# M4KN register map
File version: 0.1
Registers are 32-bit, read-write, reset 0x0 unless marked. A register's access mark holds for its fields unless they carry their own. Offsets are from the block's base; [hi:lo] are bit positions; {n}, {i} and the like mark numbered series.

## AMP — Gain Op-AMP (AMP)
Base 0x400BD000
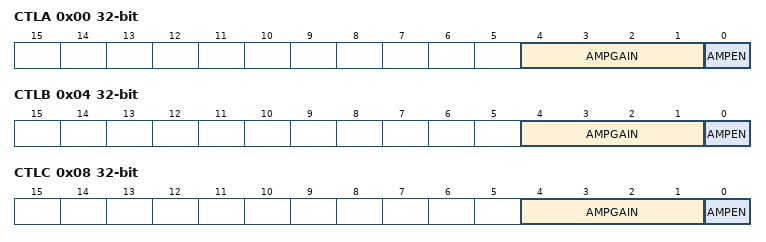
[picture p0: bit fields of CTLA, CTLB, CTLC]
0x00 CTLA — AMP control register A
  [4:1] AMPGAIN, [0] AMPEN
0x04 CTLB — AMP control register B
  [4:1] AMPGAIN, [0] AMPEN
0x08 CTLC — AMP control register C
  [4:1] AMPGAIN, [0] AMPEN

## T32A0 — 32-bit Timer Event Counter (T32A)
Base 0x400C1000
Same registers: T32A1 0x400C1400, T32A2 0x400C1800, T32A3 0x400C1C00, T32A4 0x400C2000, T32A5 0x400C2400
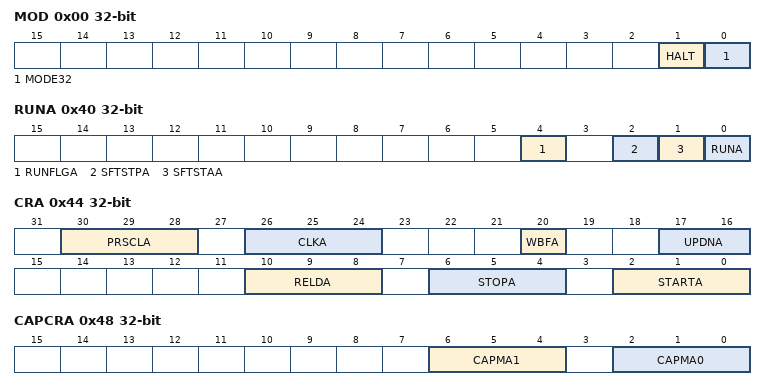
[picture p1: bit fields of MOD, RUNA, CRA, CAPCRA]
0x00 MOD — T32A Mode Register
  [1] HALT, [0] MODE32
0x40 RUNA — T32A Run Register A
  [4] RUNFLGA ro, [2] SFTSTPA wo, [1] SFTSTAA wo, [0] RUNA
0x44 CRA — T32A Control Register A
  [30:28] PRSCLA, [26:24] CLKA, [20] WBFA, [17:16] UPDNA, [10:8] RELDA, [6:4] STOPA, [2:0] STARTA
0x48 CAPCRA — T32A Capture Control Register A
  [6:4] CAPMA1, [2:0] CAPMA0
0x4C OUTCRA0 wo — T32A Output Control Register A0
  [1:0] OCRA
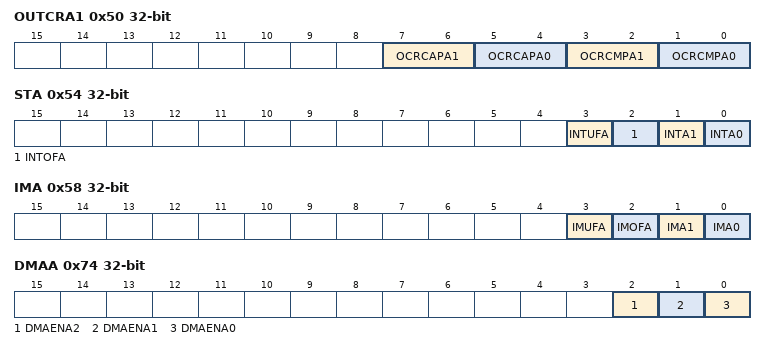
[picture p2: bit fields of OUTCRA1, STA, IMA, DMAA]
0x50 OUTCRA1 — T32A Output Control Register A1
  [7:6] OCRCAPA1, [5:4] OCRCAPA0, [3:2] OCRCMPA1, [1:0] OCRCMPA0
0x54 STA — T32A Status Register A
  [3] INTUFA, [2] INTOFA, [1] INTA1, [0] INTA0
0x58 IMA — T32A Interrupt Mask Register A
  [3] IMUFA, [2] IMOFA, [1] IMA1, [0] IMA0
0x5C TMRA ro — T32A Counter Capture Register A
  [15:0] TMRA
0x60 RELDA — T32A Reload Register A
  [15:0] RELDA
0x64 RGA0 — T32A Timer Register A0
  [15:0] RGA0
0x68 RGA1 — T32A Timer Register A1
  [15:0] RGA1
0x6C CAPA0 ro — T32A Capture Register A0
  [15:0] CAPA0
0x70 CAPA1 ro — T32A Capture Register A1
  [15:0] CAPA1
0x74 DMAA — T32A DMA Request Enable Register A
  [2] DMAENA2, [1] DMAENA1, [0] DMAENA0
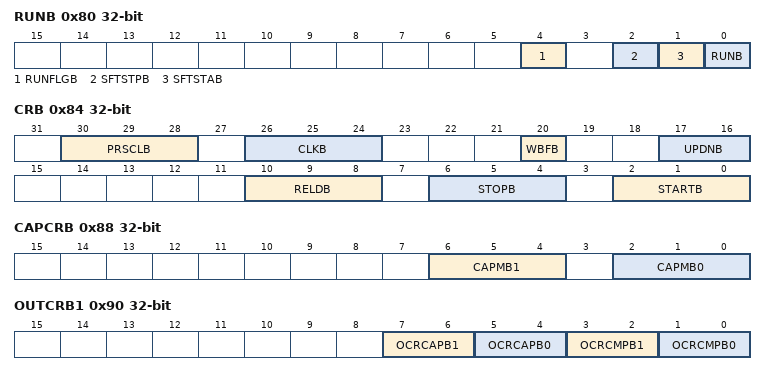
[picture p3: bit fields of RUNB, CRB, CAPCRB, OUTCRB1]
0x80 RUNB — T32A Run Register B
  [4] RUNFLGB ro, [2] SFTSTPB wo, [1] SFTSTAB wo, [0] RUNB
0x84 CRB — T32A Control Register B
  [30:28] PRSCLB, [26:24] CLKB, [20] WBFB, [17:16] UPDNB, [10:8] RELDB, [6:4] STOPB, [2:0] STARTB
0x88 CAPCRB — T32A Capture Control Register B
  [6:4] CAPMB1, [2:0] CAPMB0
0x8C OUTCRB0 wo — T32A Output Control Register B0
  [1:0] OCRB
0x90 OUTCRB1 — T32A Output Control Register B1
  [7:6] OCRCAPB1, [5:4] OCRCAPB0, [3:2] OCRCMPB1, [1:0] OCRCMPB0
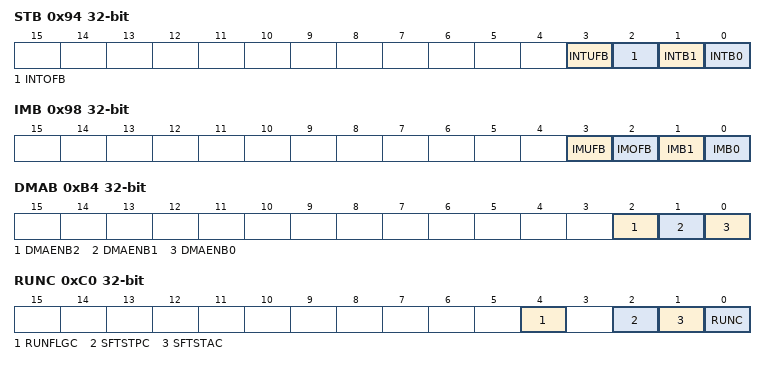
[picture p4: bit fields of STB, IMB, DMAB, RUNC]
0x94 STB — T32A Status Register B
  [3] INTUFB, [2] INTOFB, [1] INTB1, [0] INTB0
0x98 IMB — T32A Interrupt Mask Register B
  [3] IMUFB, [2] IMOFB, [1] IMB1, [0] IMB0
0x9C TMRB ro — T32A Counter Capture Register B
  [15:0] TMRB
0xA0 RELDB — T32A Reload Register B
  [15:0] RELDB
0xA4 RGB0 — T32A Timer Register B0
  [15:0] RGB0
0xA8 RGB1 — T32A Timer Register B1
  [15:0] RGB1
0xAC CAPB0 ro — T32A Capture Register B0
  [15:0] CAPB0
0xB0 CAPB1 ro — T32A Capture Register B1
  [15:0] CAPB1
0xB4 DMAB — T32A DMA Request Enable Register B
  [2] DMAENB2, [1] DMAENB1, [0] DMAENB0
0xC0 RUNC — T32A Run Register C
  [4] RUNFLGC ro, [2] SFTSTPC wo, [1] SFTSTAC wo, [0] RUNC
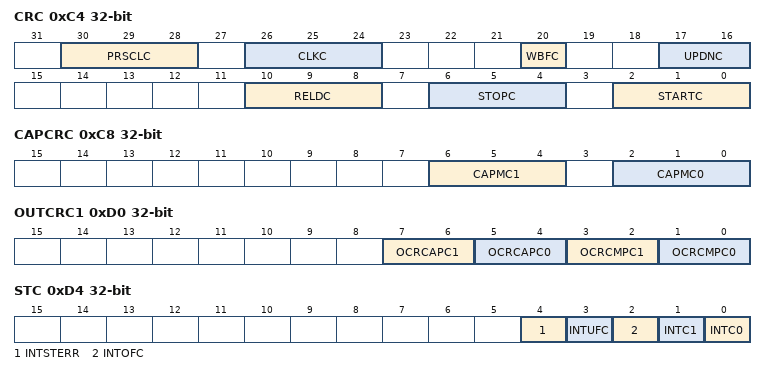
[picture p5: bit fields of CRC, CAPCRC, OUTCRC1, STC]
0xC4 CRC — T32A Control Register C
  [30:28] PRSCLC, [26:24] CLKC, [20] WBFC, [17:16] UPDNC, [10:8] RELDC, [6:4] STOPC, [2:0] STARTC
0xC8 CAPCRC — T32A Capture Control Register C
  [6:4] CAPMC1, [2:0] CAPMC0
0xCC OUTCRC0 wo — T32A Output Control Register C0
  [1:0] OCRC
0xD0 OUTCRC1 — T32A Output Control Register C1
  [7:6] OCRCAPC1, [5:4] OCRCAPC0, [3:2] OCRCMPC1, [1:0] OCRCMPC0
0xD4 STC — T32A Status Register C
  [4] INTSTERR, [3] INTUFC, [2] INTOFC, [1] INTC1, [0] INTC0
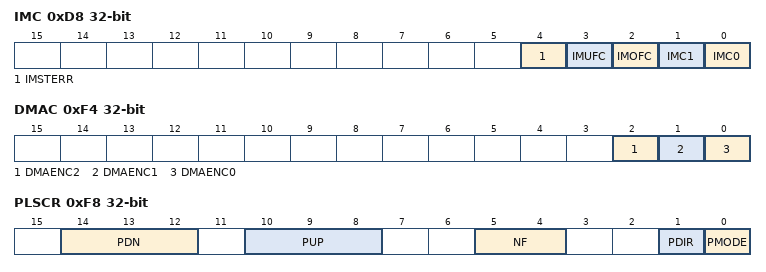
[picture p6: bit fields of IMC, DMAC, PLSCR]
0xD8 IMC — T32A Interrupt Mask Register C
  [4] IMSTERR, [3] IMUFC, [2] IMOFC, [1] IMC1, [0] IMC0
0xDC TMRC ro — T32A Counter Capture Register C
0xE0 RELDC — T32A Reload Register C
0xE4 RGC0 — T32A Timer Register C0
0xE8 RGC1 — T32A Timer Register C1
0xEC CAPC0 ro — T32A Capture Register C0
0xF0 CAPC1 ro — T32A Capture Register C1
0xF4 DMAC — T32A DMA Request Enable Register C
  [2] DMAENC2, [1] DMAENC1, [0] DMAENC0
0xF8 PLSCR — T32A Pulse Count Control Register
  [14:12] PDN, [10:8] PUP, [5:4] NF, [1] PDIR, [0] PMODE

## TSPI0 — Serial Peripheral Interface (TSPI)
Base 0x400CA000
Same registers: TSPI1 0x400CA400
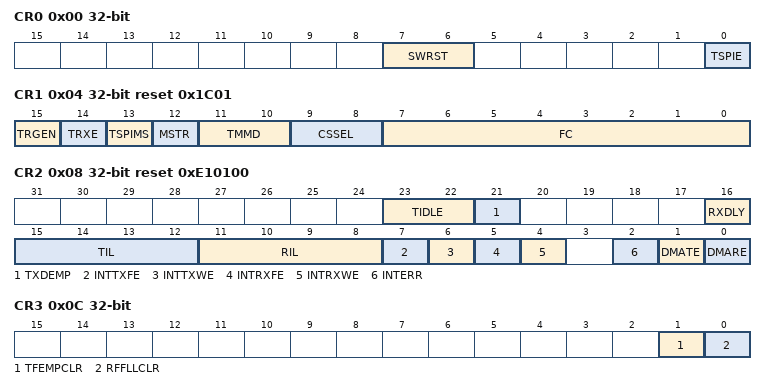
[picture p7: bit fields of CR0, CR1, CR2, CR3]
0x00 CR0 — TSPI Control Register 0
  [7:6] SWRST wo, [0] TSPIE
0x04 CR1 reset 0x1C01 — TSPI Control Register 1
  [15] TRGEN, [14] TRXE, [13] TSPIMS, [12] MSTR, [11:10] TMMD, [9:8] CSSEL, [7:0] FC
0x08 CR2 reset 0xE10100 — TSPI Control Register 2
  [23:22] TIDLE, [21] TXDEMP, [16] RXDLY, [15:12] TIL, [11:8] RIL, [7] INTTXFE, [6] INTTXWE, [5] INTRXFE, [4] INTRXWE, [2] INTERR, [1] DMATE, [0] DMARE
0x0C CR3 — TSPI Control Register 3
  [1] TFEMPCLR wo, [0] RFFLLCLR wo
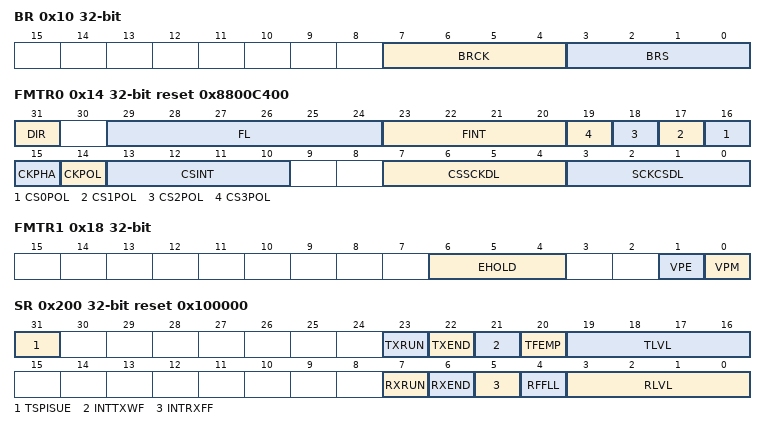
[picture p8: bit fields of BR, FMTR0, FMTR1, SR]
0x10 BR — TSPI Baud Rate Generator Control Register
  [7:4] BRCK, [3:0] BRS
0x14 FMTR0 reset 0x8800C400 — TSPI Format Control Register 0
  [31] DIR, [29:24] FL, [23:20] FINT, [n+16] CS{n}POL (n=0..3), [15] CKPHA, [14] CKPOL, [13:10] CSINT, [7:4] CSSCKDL, [3:0] SCKCSDL
0x18 FMTR1 — TSPI Format Control Register 1
  [6:4] EHOLD, [1] VPE, [0] VPM
0x100 DR — TSPI Data Register
  [31:0] TSPIDR
0x200 SR reset 0x100000 — TSPI Status Register
  [31] TSPISUE ro, [23] TXRUN ro, [22] TXEND, [21] INTTXWF, [20] TFEMP ro, [19:16] TLVL ro, [7] RXRUN ro, [6] RXEND, [5] INTRXFF, [4] RFFLL ro, [3:0] RLVL ro
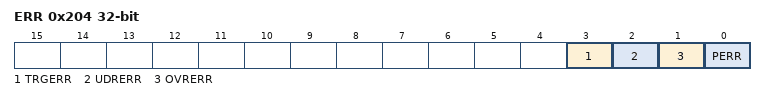
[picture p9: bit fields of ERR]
0x204 ERR — TSPI Parity Error Flag Register
  [3] TRGERR, [2] UDRERR, [1] OVRERR, [0] PERR
